# STM32MP153x register map
File version: 1.0
Registers are 32-bit, read-write, reset 0x0 unless marked. A register's access mark holds for its fields unless they carry their own. Offsets are from the block's base; [hi:lo] are bit positions; {n}, {i} and the like mark numbered series; 'fields as' and 'values as' point back to an identical list.

## ETZPC
Base 0x5C007000
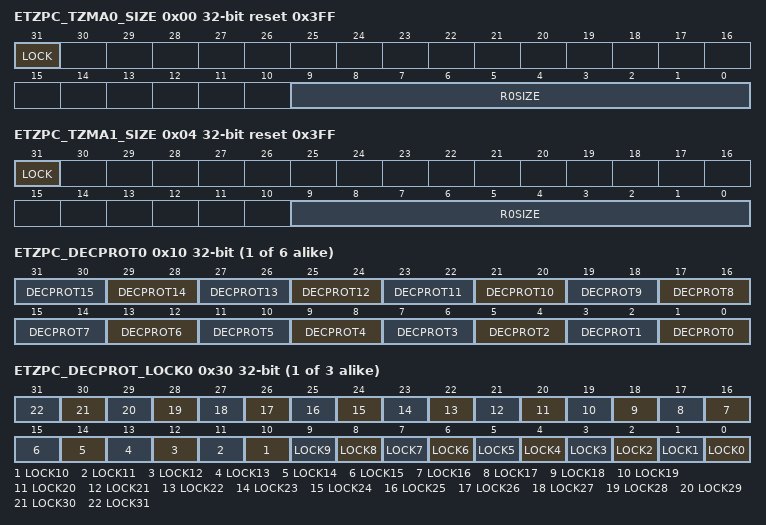
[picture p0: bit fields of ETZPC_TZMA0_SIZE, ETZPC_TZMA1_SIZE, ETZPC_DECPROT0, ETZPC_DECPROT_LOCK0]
0x00 ETZPC_TZMA0_SIZE reset 0x3FF — ETZPC ROM secure size definition
  [31] LOCK, [9:0] R0SIZE
0x04 ETZPC_TZMA1_SIZE reset 0x3FF — ETZPC RAM secure size definition
  [31] LOCK, [9:0] R0SIZE
{0x10+4i} ETZPC_DECPROT{i} (i=0..5) — Register reset values
  [2n+1:2n] DECPROT{n} (n=0..15)
{0x30+4i} ETZPC_DECPROT_LOCK{i} (i=0..2)
  [n] LOCK{n} (n=0..31)
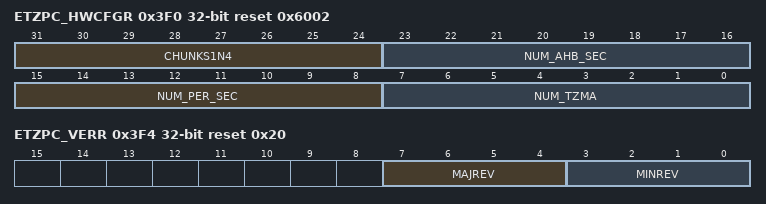
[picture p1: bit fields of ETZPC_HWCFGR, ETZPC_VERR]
0x3F0 ETZPC_HWCFGR ro reset 0x6002 — ETZPC IP HW configuration register
  [31:24] CHUNKS1N4, [23:16] NUM_AHB_SEC, [15:8] NUM_PER_SEC, [7:0] NUM_TZMA
0x3F4 ETZPC_VERR ro reset 0x20 — ETZPC IP version register
  [7:4] MAJREV, [3:0] MINREV
0x3F8 ETZPC_IDR ro reset 0x100061 — ETZPC IP version register
  [31:0] ID
0x3FC ETZPC_SIDR ro reset 0xA3C5DD01 — ETZPC IP version register
  [31:0] SID

## IWDG1
Base 0x5C003000
Same registers: IWDG2 0x5A002000
0x00 IWDG_KR wo — Key register
  [15:0] KEY
0x04 IWDG_PR reset 0x7 — Prescaler register
  [2:0] PR
0x08 IWDG_RLR reset 0xFFF — Reload register
  [11:0] RL
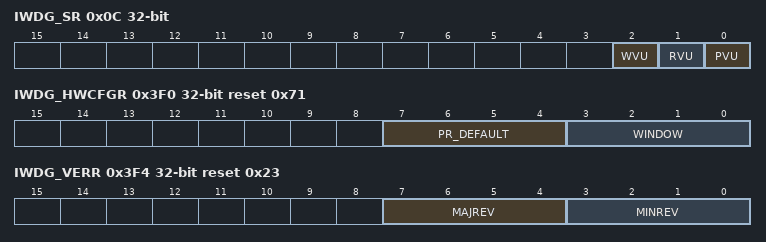
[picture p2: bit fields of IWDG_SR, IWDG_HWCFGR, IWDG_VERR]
0x0C IWDG_SR ro — Status register
  [2] WVU, [1] RVU, [0] PVU
0x10 IWDG_WINR reset 0xFFF — Window register
  [11:0] WIN
0x3F0 IWDG_HWCFGR ro reset 0x71 — IWDG hardware configuration register
  [7:4] PR_DEFAULT, [3:0] WINDOW
0x3F4 IWDG_VERR ro reset 0x23 — IWDG version register
  [7:4] MAJREV, [3:0] MINREV
0x3F8 IWDG_IDR ro reset 0x120041 — IWDG identification register
  [31:0] ID
0x3FC IWDG_SIDR ro reset 0xA3C5DD01 — IWDG size identification register
  [31:0] SID

## USBPHYC
Base 0x5A006000
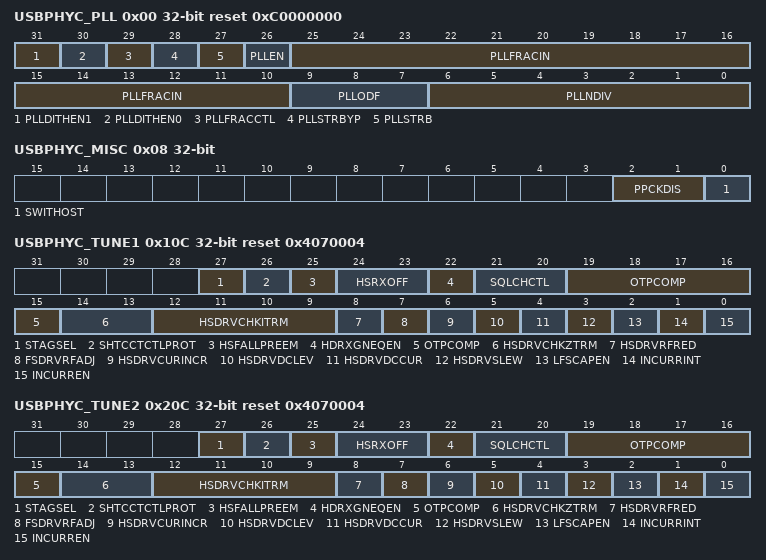
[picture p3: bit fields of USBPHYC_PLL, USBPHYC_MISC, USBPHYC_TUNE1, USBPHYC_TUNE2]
0x00 USBPHYC_PLL reset 0xC0000000 — This register is used to control the PLL of the HS PHY.
  [31] PLLDITHEN1, [30] PLLDITHEN0, [29] PLLFRACCTL, [28] PLLSTRBYP, [27] PLLSTRB, [26] PLLEN, [25:10] PLLFRACIN, [9:7] PLLODF, [6:0] PLLNDIV
0x08 USBPHYC_MISC — This register is used to control the switch between controllers for the HS PHY.
  [2:1] PPCKDIS, [0] SWITHOST
0x10C USBPHYC_TUNE1 reset 0x4070004 — This register is used to control the tune interface of the HS PHY, port #x.
  [27] STAGSEL, [26] SHTCCTCTLPROT, [25] HSFALLPREEM, [24:23] HSRXOFF, [22] HDRXGNEQEN, [21:20] SQLCHCTL, [19:15] OTPCOMP, [14:13] HSDRVCHKZTRM, [12:9] HSDRVCHKITRM, [8] HSDRVRFRED, [7] FSDRVRFADJ, [6] HSDRVCURINCR, [5] HSDRVDCLEV, [4] HSDRVDCCUR, [3] HSDRVSLEW, [2] LFSCAPEN, [1] INCURRINT, [0] INCURREN
0x20C USBPHYC_TUNE2 reset 0x4070004 — This register is used to control the tune interface of the HS PHY, port #x.
  fields as USBPHYC_TUNE1
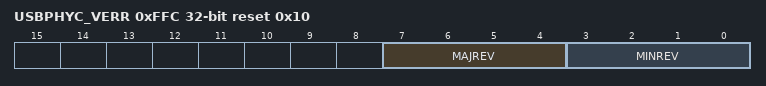
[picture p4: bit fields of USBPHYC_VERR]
0xFFC USBPHYC_VERR ro reset 0x10 — This register defines the version of this IP.
  [7:4] MAJREV, [3:0] MINREV

## CRC1
Base 0x58009000
Same registers: CRC2 0x4C004000
0x00 CRC_DR reset 0xFFFFFFFF — CRC data register
0x04 CRC_IDR — CRC independent data register
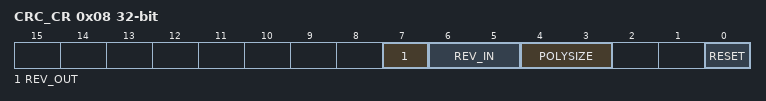
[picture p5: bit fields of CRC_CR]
0x08 CRC_CR — CRC control register
  [7] REV_OUT, [6:5] REV_IN, [4:3] POLYSIZE, [0] RESET
0x10 CRC_INIT reset 0xFFFFFFFF — CRC initial value
0x14 CRC_POL reset 0x4C11DB7 — CRC polynomial

## QUADSPI — QUADSPI1
Base 0x58003000
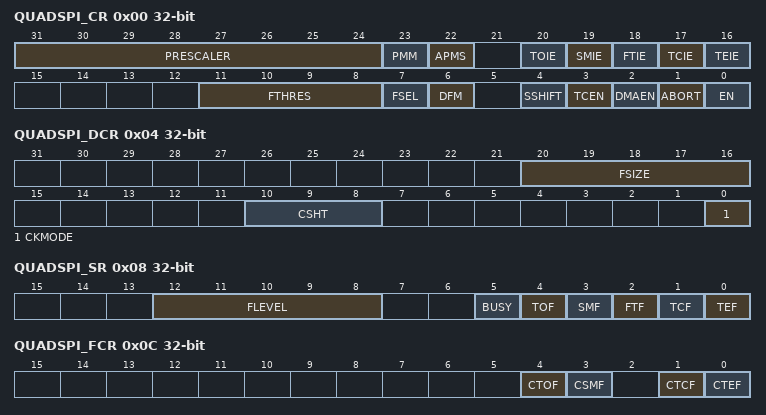
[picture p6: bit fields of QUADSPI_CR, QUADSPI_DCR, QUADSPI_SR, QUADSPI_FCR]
0x00 QUADSPI_CR — QUADSPI control register
  [31:24] PRESCALER, [23] PMM, [22] APMS, [20] TOIE, [19] SMIE, [18] FTIE, [17] TCIE, [16] TEIE, [11:8] FTHRES, [7] FSEL, [6] DFM, [4] SSHIFT, [3] TCEN, [2] DMAEN, [1] ABORT, [0] EN
0x04 QUADSPI_DCR — QUADSPI device configuration register
  [20:16] FSIZE, [10:8] CSHT, [0] CKMODE
0x08 QUADSPI_SR ro — QUADSPI status register
  [12:8] FLEVEL, [5] BUSY, [4] TOF, [3] SMF, [2] FTF, [1] TCF, [0] TEF
0x0C QUADSPI_FCR wo — QUADSPI flag clear register
  [4] CTOF, [3] CSMF, [1] CTCF, [0] CTEF
0x10 QUADSPI_DLR — QUADSPI data length register
  [31:0] DL
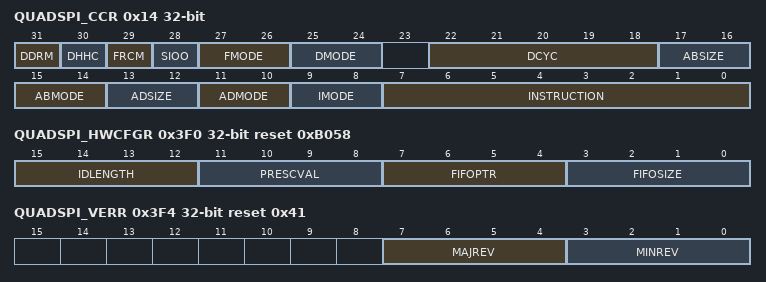
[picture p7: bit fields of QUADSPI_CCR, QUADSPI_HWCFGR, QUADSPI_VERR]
0x14 QUADSPI_CCR — QUADSPI communication configuration register
  [31] DDRM, [30] DHHC, [29] FRCM, [28] SIOO, [27:26] FMODE, [25:24] DMODE, [22:18] DCYC, [17:16] ABSIZE, [15:14] ABMODE, [13:12] ADSIZE, [11:10] ADMODE, [9:8] IMODE, [7:0] INSTRUCTION
0x18 QUADSPI_AR — QUADSPI address register
  [31:0] ADDRESS
0x1C QUADSPI_ABR — QUADSPI alternate bytes registers
  [31:0] ALTERNATE
0x20 QUADSPI_DR — QUADSPI data register
  [31:0] DATA
0x24 QUADSPI_PSMKR — QUADSPI polling status mask register
  [31:0] MASK
0x28 QUADSPI_PSMAR — QUADSPI polling status match register
  [31:0] MATCH
0x2C QUADSPI_PIR — QUADSPI polling interval register
  [15:0] INTERVAL
0x30 QUADSPI_LPTR — QUADSPI low-power timeout register
  [15:0] TIMEOUT
0x3F0 QUADSPI_HWCFGR ro reset 0xB058 — QUADSPI HW configuration register
  [15:12] IDLENGTH, [11:8] PRESCVAL, [7:4] FIFOPTR, [3:0] FIFOSIZE
0x3F4 QUADSPI_VERR ro reset 0x41 — QUADSPI version register
  [7:4] MAJREV, [3:0] MINREV
0x3F8 QUADSPI_IPIDR ro reset 0x140031 — QUADSPI identification register
  [31:0] ID
0x3FC QUADSPI_SIDR ro reset 0xA3C5DD01 — QUADSPI size identification register
  [31:0] SID
